# S6E1B8xG register map
Vendor: Cypress; File version: 2.1
CPU: CM0PLUS r0p1, little endian, no MPU, no FPU, 2 interrupt priority bits
Registers are 8-bit, read-write, reset 0x0 unless marked. A register's access mark holds for its fields unless they carry their own. Offsets are from the block's base; [hi:lo] are bit positions; {n}, {i} and the like mark numbered series.

## DS — Low Power Consumption Mode Registers
Base 0x40035100
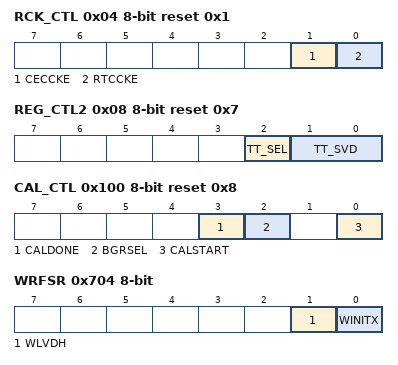
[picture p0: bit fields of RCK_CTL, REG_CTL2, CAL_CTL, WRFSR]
0x04 RCK_CTL reset 0x1 — Sub Clock Control Register [BHW]
  [1] CECCKE — CEC clock control bit
  [0] RTCCKE — RTC clock control bit
0x08 REG_CTL2 reset 0x7 — Internal Voltage Control Register [BHW]
  [2] TT_SEL — Function enable bit
  [1:0] TT_SVD — Internalvoltage setting bit
0x10 MOSC_CTL reset 0x4 — Main Oscillation Crystal Type Selection Control Register [BHW]
  [2:1] IMAINSEL — Main oscillation circuit current setting bits
0x100 CAL_CTL reset 0x8 — Vref Calibration Control Register [BHW]
  [3] CALDONE ro — Vref Calibration Done Flag
  [2] BGRSEL — Vref Select Bit
  [0] CALSTART — Vref Calibration Start Bit
0x104 CAL_SET reset 0x11 — Vref Calibration Value Register [BHW]
  [4:0] DSTB — Vref Calibration Value
0x108 CAL_KEY 32-bit reset 0x1 — Vref Calibration Security Key Register [W]
0x700 PMD_CTL — RTC Mode Control Register [BHW]
  [0] RTCE — RTC mode control bit
0x704 WRFSR ro — Deep Standby Return Factor Register 1 [BHW]
  [1] WLVDH — Low-voltage detection reset return bit
  [0] WINITX — INITX pin input reset return bit
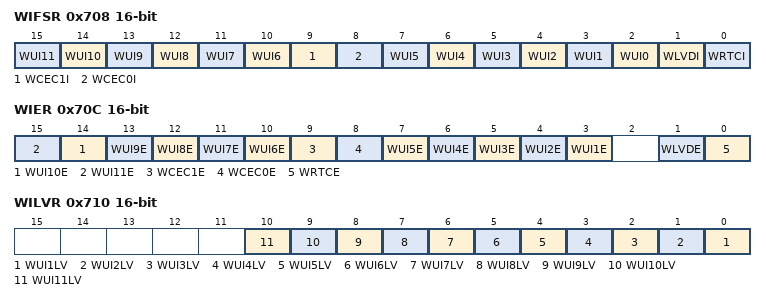
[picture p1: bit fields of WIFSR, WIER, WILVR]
0x708 WIFSR 16-bit ro — Deep Standby Return Factor Register 2 [BHW]
  [n+4] WUI{n} (n=6..11) — WKUP{n} pin input return bit
  [9] WCEC1I — CEC ch.1 interrupt return bit
  [8] WCEC0I — CEC ch.0 interrupt return bit
  [n+2] WUI{n} (n=0..5) — WKUP{n} pin input return bit
  [1] WLVDI — LVD interrupt return bit
  [0] WRTCI — RTC interrupt return bit
0x70C WIER 16-bit — Deep Standby Return Enable Register [BHW]
  [n+4] WUI{n}E ro (n=6..11) — WKUP{n} pin input return enable bit
  [9] WCEC1E — HDMI-CEC/ Remote Control Reception ch.1 interrupt return enable bit
  [8] WCEC0E — HDMI-CEC/ Remote Control Reception ch.0 interrupt return enable bit
  [n+2] WUI{n}E (n=1..5) — WKUP{n} pin input return enable bit
  [1] WLVDE — LVD interrupt return enable bit
  [0] WRTCE — RTC interrupt return enable bit
0x710 WILVR 16-bit — WKUP Pin Input Level Register [BHW]
  [n-1] WUI{n}LV (n=1..11) — WKUP{n} pin input level select bit
0x714 DSRAMR — Deep Standby RAM Retention Register [BHW]
  [1:0] SRAMR — On-chip SRAM retention control bits
0x720 STBFLASHPDX — Flash Power Down In Stop/Rtc/Sub Timer Mode Register [BHW]
  [0] STBFLASHPDX — Flash Power Down in Stop/Rtc/Sub Timer Mode Bit
{0x7FF+i} BUR{i:02} (i=1..16) — Backup Register {i:02} [BHW]

## USBCLK — USB/Ethernet Clock
Base 0x40036000
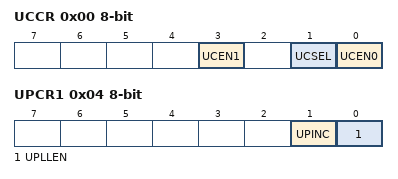
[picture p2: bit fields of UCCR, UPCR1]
0x00 UCCR — USB Clock Control Register [BHW]
  [3] UCEN1 — USB1 clock output enable bit
  [1] UCSEL — USB clock selection bit
  [0] UCEN0 — USB0 clock output enable bit
0x04 UPCR1 — USB-PLL Control Register 1 [BHW]
  [1] UPINC — USB-PLL input clock selection bit
  [0] UPLLEN — USB-PLL oscillation enable bit
0x08 UPCR2 — USB-PLL Control Register 2 [BHW]
  [2:0] UPOWT — USB-PLL oscillation stabilization wait time setting bit
0x0C UPCR3 — USB-PLL Control Register 3 [BHW]
  [4:0] UPLLK — Frequency division ratio (K) setting bit of the USB-PLL clock
0x10 UPCR4 reset 0x3B — USB-PLL Control Register 4 [BHW]
  [6:0] UPLLN — Frequency division ratio (N) setting bit of the USB-PLL clock
0x14 UP_STR ro — USB-PLL Status Register [BHW]
  [0] UPRDY — USB-PLL oscillation stabilization bit
0x18 UPINT_ENR — USB-PLL Interrupt Factor Enable Register [BHW]
  [0] UPCSE — USB-PLL oscillation stabilization wait complete interrupt enable bit
0x1C UPINT_CLR wo — USB-PLL Interrupt Factor Clear Register [BHW]
  [0] UPCSC — USB-PLL oscillation stabilization interrupt factor clear bit
0x20 UPINT_STR ro — USB-PLL Interrupt Factor Status Register [BHW]
  [0] UPCSI — USB-PLL interrupt factor status bit
0x24 UPCR5 reset 0x4 — USB-PLL Control Register 5 [BHW]
  [3:0] UPLLM — Frequency division ratio (M) setting bit of the USB-PLL clock
0x30 USBEN0 reset 0x4 — USB0 Enable Register [BHW]
  [0] USBEN0 — USB0 enable bit
0x34 USBEN1 reset 0x4 — USB1 Enable Register [BHW]
  [0] USBEN1 — USB1 enable bit
